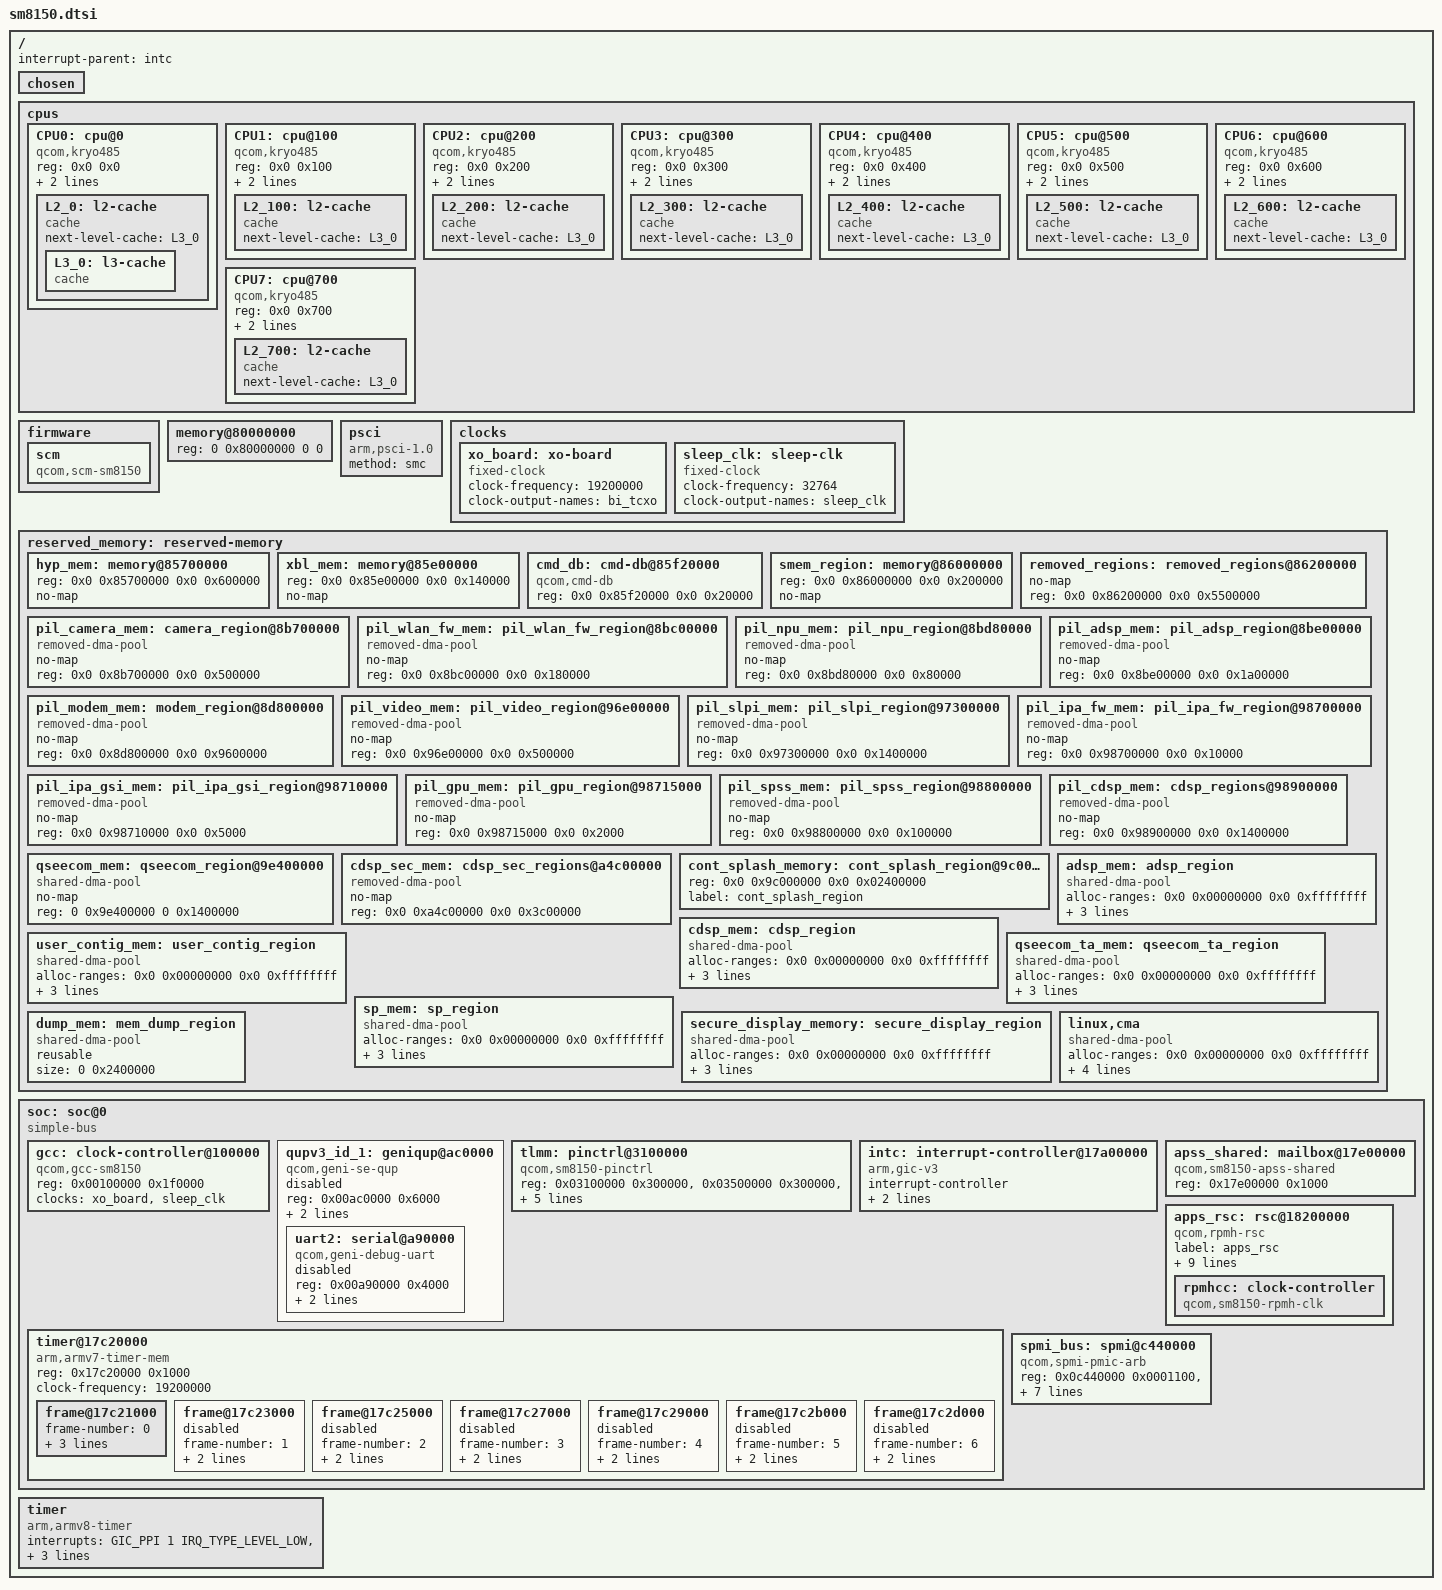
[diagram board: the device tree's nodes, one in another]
// SPDX-License-Identifier: GPL-2.0
// Copyright (c) 2017-19, The Linux Foundation. All rights reserved.
// Copyright (c) 2019, Linaro Limited

#include <dt-bindings/interrupt-controller/arm-gic.h>
#include <dt-bindings/clock/qcom,gcc-sm8150.h>
#include <dt-bindings/soc/qcom,rpmh-rsc.h>

/ {
	interrupt-parent = <&intc>;

	#address-cells = <2>;
	#size-cells = <2>;

	chosen { };

	cpus {
		#address-cells = <2>;
		#size-cells = <0>;

		CPU0: cpu@0 {
			device_type = "cpu";
			compatible = "qcom,kryo485";
			reg = <0x0 0x0>;
			enable-method = "psci";
			next-level-cache = <&L2_0>;
			L2_0: l2-cache {
				compatible = "cache";
				next-level-cache = <&L3_0>;
				L3_0: l3-cache {
				      compatible = "cache";
				};
			};
		};

		CPU1: cpu@100 {
			device_type = "cpu";
			compatible = "qcom,kryo485";
			reg = <0x0 0x100>;
			enable-method = "psci";
			next-level-cache = <&L2_100>;
			L2_100: l2-cache {
				compatible = "cache";
				next-level-cache = <&L3_0>;
			};

		};

		CPU2: cpu@200 {
			device_type = "cpu";
			compatible = "qcom,kryo485";
			reg = <0x0 0x200>;
			enable-method = "psci";
			next-level-cache = <&L2_200>;
			L2_200: l2-cache {
				compatible = "cache";
				next-level-cache = <&L3_0>;
			};
		};

		CPU3: cpu@300 {
			device_type = "cpu";
			compatible = "qcom,kryo485";
			reg = <0x0 0x300>;
			enable-method = "psci";
			next-level-cache = <&L2_300>;
			L2_300: l2-cache {
				compatible = "cache";
				next-level-cache = <&L3_0>;
			};
		};

		CPU4: cpu@400 {
			device_type = "cpu";
			compatible = "qcom,kryo485";
			reg = <0x0 0x400>;
			enable-method = "psci";
			next-level-cache = <&L2_400>;
			L2_400: l2-cache {
				compatible = "cache";
				next-level-cache = <&L3_0>;
			};
		};

		CPU5: cpu@500 {
			device_type = "cpu";
			compatible = "qcom,kryo485";
			reg = <0x0 0x500>;
			enable-method = "psci";
			next-level-cache = <&L2_500>;
			L2_500: l2-cache {
				compatible = "cache";
				next-level-cache = <&L3_0>;
			};
		};

		CPU6: cpu@600 {
			device_type = "cpu";
			compatible = "qcom,kryo485";
			reg = <0x0 0x600>;
			enable-method = "psci";
			next-level-cache = <&L2_600>;
			L2_600: l2-cache {
				compatible = "cache";
				next-level-cache = <&L3_0>;
			};
		};

		CPU7: cpu@700 {
			device_type = "cpu";
			compatible = "qcom,kryo485";
			reg = <0x0 0x700>;
			enable-method = "psci";
			next-level-cache = <&L2_700>;
			L2_700: l2-cache {
				compatible = "cache";
				next-level-cache = <&L3_0>;
			};
		};
	};

	firmware {
		scm: scm {
			compatible = "qcom,scm-sm8150", "qcom,scm";
			#reset-cells = <1>;
		};
	};

	memory@80000000 {
		device_type = "memory";
		/* We expect the bootloader to fill in the size */
		reg = <0 0x80000000 0 0>;
	};

	psci {
		compatible = "arm,psci-1.0";
		method = "smc";
	};

	clocks {
		xo_board: xo-board {
			compatible = "fixed-clock";
			#clock-cells = <0>;
			clock-frequency = <19200000>;
			clock-output-names = "bi_tcxo";
		};

		sleep_clk: sleep-clk {
			compatible = "fixed-clock";
			#clock-cells = <0>;
			clock-frequency = <32764>;
			clock-output-names = "sleep_clk";
		};
	};

	reserved_memory: reserved-memory {
		#address-cells = <2>;
		#size-cells = <2>;
		ranges;

		hyp_mem: memory@85700000 {
			reg = <0x0 0x85700000 0x0 0x600000>;
			no-map;
		};

		xbl_mem: memory@85e00000 {
			reg = <0x0 0x85e00000 0x0 0x140000>;
			no-map;
		};

		cmd_db: cmd-db@85f20000 {
			compatible = "qcom,cmd-db";
			reg = <0x0 0x85f20000 0x0 0x20000>;
		};

		smem_region: memory@86000000 {
			reg = <0x0 0x86000000 0x0 0x200000>;
			no-map;
		};

		removed_regions: removed_regions@86200000 {
			no-map;
			reg = <0x0 0x86200000 0x0 0x5500000>;
		};

		pil_camera_mem: camera_region@8b700000 {
			compatible = "removed-dma-pool";
			no-map;
			reg = <0x0 0x8b700000 0x0 0x500000>;
		};

		pil_wlan_fw_mem: pil_wlan_fw_region@8bc00000 {
			compatible = "removed-dma-pool";
			no-map;
			reg = <0x0 0x8bc00000 0x0 0x180000>;
		};

		pil_npu_mem: pil_npu_region@8bd80000 {
			compatible = "removed-dma-pool";
			no-map;
			reg = <0x0 0x8bd80000 0x0 0x80000>;
		};

		pil_adsp_mem: pil_adsp_region@8be00000 {
			compatible = "removed-dma-pool";
			no-map;
			reg = <0x0 0x8be00000 0x0 0x1a00000>;
		};

		pil_modem_mem: modem_region@8d800000 {
			compatible = "removed-dma-pool";
			no-map;
			reg = <0x0 0x8d800000 0x0 0x9600000>;
		};

		pil_video_mem: pil_video_region@96e00000 {
			compatible = "removed-dma-pool";
			no-map;
			reg = <0x0 0x96e00000 0x0 0x500000>;
		};

		pil_slpi_mem: pil_slpi_region@97300000 {
			compatible = "removed-dma-pool";
			no-map;
			reg = <0x0 0x97300000 0x0 0x1400000>;
		};

		pil_ipa_fw_mem: pil_ipa_fw_region@98700000 {
			compatible = "removed-dma-pool";
			no-map;
			reg = <0x0 0x98700000 0x0 0x10000>;
		};

		pil_ipa_gsi_mem: pil_ipa_gsi_region@98710000 {
			compatible = "removed-dma-pool";
			no-map;
			reg = <0x0 0x98710000 0x0 0x5000>;
		};

		pil_gpu_mem: pil_gpu_region@98715000 {
			compatible = "removed-dma-pool";
			no-map;
			reg = <0x0 0x98715000 0x0 0x2000>;
		};

		pil_spss_mem: pil_spss_region@98800000 {
			compatible = "removed-dma-pool";
			no-map;
			reg = <0x0 0x98800000 0x0 0x100000>;
		};

		pil_cdsp_mem: cdsp_regions@98900000 {
			compatible = "removed-dma-pool";
			no-map;
			reg = <0x0 0x98900000 0x0 0x1400000>;
		};

		qseecom_mem: qseecom_region@9e400000 {
			compatible = "shared-dma-pool";
			no-map;
			reg = <0 0x9e400000 0 0x1400000>;
		};

		cdsp_sec_mem: cdsp_sec_regions@a4c00000 {
			compatible = "removed-dma-pool";
			no-map;
			reg = <0x0 0xa4c00000 0x0 0x3c00000>;
		};

		cont_splash_memory: cont_splash_region@9c000000 {
			reg = <0x0 0x9c000000 0x0 0x02400000>;
			label = "cont_splash_region";
		};

		adsp_mem: adsp_region {
			compatible = "shared-dma-pool";
			alloc-ranges = <0x0 0x00000000 0x0 0xffffffff>;
			reusable;
			alignment = <0x0 0x400000>;
			size = <0x0 0x1000000>;
		};

		cdsp_mem: cdsp_region {
			compatible = "shared-dma-pool";
			alloc-ranges = <0x0 0x00000000 0x0 0xffffffff>;
			reusable;
			alignment = <0x0 0x400000>;
			size = <0x0 0x400000>;
		};

		user_contig_mem: user_contig_region {
			compatible = "shared-dma-pool";
			alloc-ranges = <0x0 0x00000000 0x0 0xffffffff>;
			reusable;
			alignment = <0x0 0x400000>;
			size = <0x0 0x1000000>;
		};

		qseecom_ta_mem: qseecom_ta_region {
			compatible = "shared-dma-pool";
			alloc-ranges = <0x0 0x00000000 0x0 0xffffffff>;
			reusable;
			alignment = <0x0 0x400000>;
			size = <0x0 0x1000000>;
		};

		sp_mem: sp_region {  /* SPSS-HLOS ION shared mem */
			compatible = "shared-dma-pool";
			alloc-ranges = <0x0 0x00000000 0x0 0xffffffff>;
			reusable;
			alignment = <0x0 0x400000>;
			size = <0x0 0x800000>;
		};

		secure_display_memory: secure_display_region { /* Secure UI */
			compatible = "shared-dma-pool";
			alloc-ranges = <0x0 0x00000000 0x0 0xffffffff>;
			reusable;
			alignment = <0x0 0x400000>;
			size = <0x0 0xA000000>;
		};

		dump_mem: mem_dump_region {
			compatible = "shared-dma-pool";
			reusable;
			size = <0 0x2400000>;
		};

		/* global autoconfigured region for contiguous allocations */
		linux,cma {
			compatible = "shared-dma-pool";
			alloc-ranges = <0x0 0x00000000 0x0 0xffffffff>;
			reusable;
			alignment = <0x0 0x400000>;
			size = <0x0 0x2800000>;
			linux,cma-default;
		};
	};


	soc: soc@0 {
		#address-cells = <1>;
		#size-cells = <1>;
		ranges = <0 0 0 0xffffffff>;
		compatible = "simple-bus";

		gcc: clock-controller@100000 {
			compatible = "qcom,gcc-sm8150";
			reg = <0x00100000 0x1f0000>;
			#clock-cells = <1>;
			#reset-cells = <1>;
			#power-domain-cells = <1>;
			clock-names = "bi_tcxo",
				      "sleep_clk";
			//clocks = <&rpmcc RPM_SMD_XO_CLK_SRC>;
			clocks = <&xo_board>, <&sleep_clk>;
		};

		qupv3_id_1: geniqup@ac0000 {
			compatible = "qcom,geni-se-qup";
			reg = <0x00ac0000 0x6000>;
			clock-names = "m-ahb", "s-ahb";
			clocks = <&gcc GCC_QUPV3_WRAP_1_M_AHB_CLK>,
				 <&gcc GCC_QUPV3_WRAP_1_S_AHB_CLK>;
			#address-cells = <1>;
			#size-cells = <1>;
			ranges;
			status = "disabled";

			uart2: serial@a90000 {
				compatible = "qcom,geni-debug-uart";
				reg = <0x00a90000 0x4000>;
				clock-names = "se";
				clocks = <&gcc GCC_QUPV3_WRAP1_S4_CLK>;
				//pinctrl-names = "default";
				//pinctrl-0 = <&qup_uart0_default>;
				interrupts = <GIC_SPI 357 IRQ_TYPE_LEVEL_HIGH>;
				status = "disabled";
			};
		};

		tlmm: pinctrl@3100000 {
			compatible = "qcom,sm8150-pinctrl";
			reg = <0x03100000 0x300000>,
			      <0x03500000 0x300000>,
			      <0x03900000 0x300000>,
			      <0x03D00000 0x300000>;
			reg-names = "west", "east", "north", "south";
			interrupts = <GIC_SPI 208 IRQ_TYPE_LEVEL_HIGH>;
			gpio-ranges = <&tlmm 0 0 175>;
			gpio-controller;
			#gpio-cells = <2>;
			interrupt-controller;
			#interrupt-cells = <2>;
		};

		intc: interrupt-controller@17a00000 {
			compatible = "arm,gic-v3";
			interrupt-controller;
			#interrupt-cells = <3>;
			reg = <0x17a00000 0x10000>,	/* GICD */
			      <0x17a60000 0x100000>;	/* GICR * 8 */
			interrupts = <GIC_PPI 9 IRQ_TYPE_LEVEL_HIGH>;
		};

		timer@17c20000 {
			#address-cells = <1>;
			#size-cells = <1>;
			ranges;
			compatible = "arm,armv7-timer-mem";
			reg = <0x17c20000 0x1000>;
			clock-frequency = <19200000>;

			frame@17c21000{
				frame-number = <0>;
				interrupts = <GIC_SPI 8 IRQ_TYPE_LEVEL_HIGH>,
					     <GIC_SPI 6 IRQ_TYPE_LEVEL_HIGH>;
				reg = <0x17c21000 0x1000>,
				      <0x17c22000 0x1000>;
			};

			frame@17c23000 {
				frame-number = <1>;
				interrupts = <GIC_SPI 9 IRQ_TYPE_LEVEL_HIGH>;
				reg = <0x17c23000 0x1000>;
				status = "disabled";
			};

			frame@17c25000 {
				frame-number = <2>;
				interrupts = <GIC_SPI 10 IRQ_TYPE_LEVEL_HIGH>;
				reg = <0x17c25000 0x1000>;
				status = "disabled";
			};

			frame@17c27000 {
				frame-number = <3>;
				interrupts = <GIC_SPI 11 IRQ_TYPE_LEVEL_HIGH>;
				reg = <0x17c26000 0x1000>;
				status = "disabled";
			};

			frame@17c29000 {
				frame-number = <4>;
				interrupts = <GIC_SPI 12 IRQ_TYPE_LEVEL_HIGH>;
				reg = <0x17c29000 0x1000>;
				status = "disabled";
			};

			frame@17c2b000 {
				frame-number = <5>;
				interrupts = <GIC_SPI 13 IRQ_TYPE_LEVEL_HIGH>;
				reg = <0x17c2b000 0x1000>;
				status = "disabled";
			};

			frame@17c2d000 {
				frame-number = <6>;
				interrupts = <GIC_SPI 14 IRQ_TYPE_LEVEL_HIGH>;
				reg = <0x17c2d000 0x1000>;
				status = "disabled";
			};
		};

		apss_shared: mailbox@17e00000 {
			compatible = "qcom,sm8150-apss-shared";
			reg = <0x17e00000 0x1000>;
			#mbox-cells = <1>;
		};

		apps_rsc: rsc@18200000 {
			label = "apps_rsc";
			compatible = "qcom,rpmh-rsc";
			reg = <0x18200000 0x10000>,
			      <0x18210000 0x10000>,
			      <0x18220000 0x10000>;
			reg-names = "drv-0", "drv-1", "drv-2";
			interrupts = <GIC_SPI 3 IRQ_TYPE_LEVEL_HIGH>,
				     <GIC_SPI 4 IRQ_TYPE_LEVEL_HIGH>,
				     <GIC_SPI 5 IRQ_TYPE_LEVEL_HIGH>;
			qcom,tcs-offset = <0xd00>;
			qcom,drv-id = <2>;
			qcom,tcs-config = <ACTIVE_TCS  2>,
					  <SLEEP_TCS   1>,
					  <WAKE_TCS    1>,
					  <CONTROL_TCS 0>;

			rpmhcc: clock-controller {
				compatible = "qcom,sm8150-rpmh-clk";
				#clock-cells = <1>;
			};
		};

		spmi_bus: spmi@c440000 {
			compatible = "qcom,spmi-pmic-arb";
			reg = <0x0c440000 0x0001100>,
			      <0x0c600000 0x2000000>,
			      <0x0e600000 0x0100000>,
			      <0x0e700000 0x00a0000>,
			      <0x0c40a000 0x0026000>;
			reg-names = "core", "chnls", "obsrvr", "intr", "cnfg";
			interrupt-names = "periph_irq";
			interrupts = <GIC_SPI 481 IRQ_TYPE_LEVEL_HIGH>;
			qcom,ee = <0>;
			qcom,channel = <0>;
			#address-cells = <2>;
			#size-cells = <0>;
			interrupt-controller;
			#interrupt-cells = <4>;
			cell-index = <0>;
		};
	};

	timer {
		compatible = "arm,armv8-timer";
		interrupts = <GIC_PPI 1 IRQ_TYPE_LEVEL_LOW>,
			     <GIC_PPI 2 IRQ_TYPE_LEVEL_LOW>,
			     <GIC_PPI 3 IRQ_TYPE_LEVEL_LOW>,
			     <GIC_PPI 0 IRQ_TYPE_LEVEL_LOW>;
	};
};
